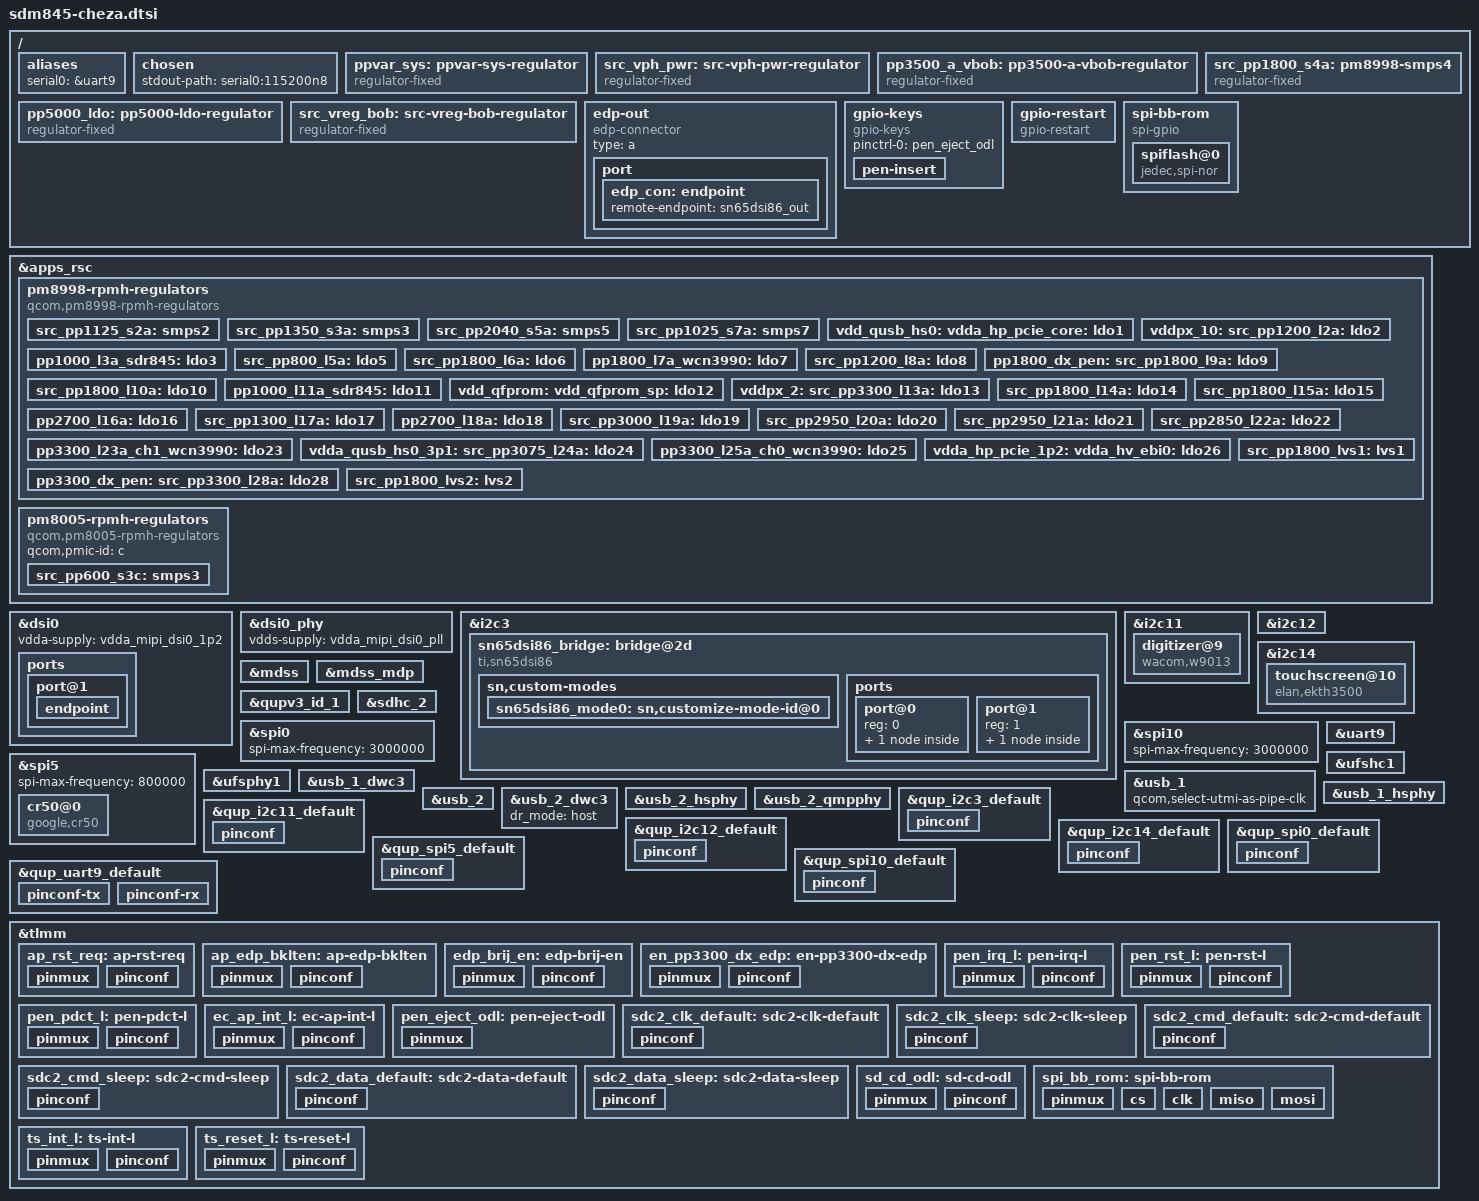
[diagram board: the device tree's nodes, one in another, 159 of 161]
// SPDX-License-Identifier: (GPL-2.0+ OR MIT)
/*
 * Google Cheza device tree source (common between revisions)
 *
 * Copyright 2018 Google LLC.
 */

#include <dt-bindings/gpio/gpio.h>
#include <dt-bindings/input/input.h>
#include <dt-bindings/regulator/qcom,rpmh-regulator.h>
#include "sdm845.dtsi"

/* PMICs depend on spmi_bus label and so must come after SoC */
#include "pm8005.dtsi"
#include "pm8998.dtsi"

/ {
	aliases {
		serial0 = &uart9;
	};

	chosen {
		stdout-path = "serial0:115200n8";
	};

	/* FIXED REGULATORS - parents above childeren */

	ppvar_sys: ppvar-sys-regulator {
		compatible = "regulator-fixed";
		regulator-name = "ppvar_sys";
		regulator-always-on;
		regulator-boot-on;
	};

	src_vph_pwr: src-vph-pwr-regulator {
		compatible = "regulator-fixed";
		regulator-name = "src_vph_pwr";

		/* EC turns on with switchcap_on_l; always on for AP */
		regulator-always-on;
		regulator-boot-on;

		/* TODO: What voltage? */

		vin-supply = <&ppvar_sys>;
	};

	pp3500_a_vbob: pp3500-a-vbob-regulator {
		compatible = "regulator-fixed";
		regulator-name = "vreg_bob";

		/* Comes on automatically when pp5000_ldo comes on */
		regulator-always-on;
		regulator-boot-on;
		regulator-min-microvolt = <3500000>;
		regulator-max-microvolt = <3500000>;

		vin-supply = <&ppvar_sys>;
	};

	pp5000_ldo: pp5000-ldo-regulator {
		compatible = "regulator-fixed";
		regulator-name = "pp5000_ldo";

		/* EC turns on with en_pp5000_a; always on for AP */
		regulator-always-on;
		regulator-boot-on;
		regulator-min-microvolt = <5000000>;
		regulator-max-microvolt = <5000000>;

		vin-supply = <&ppvar_sys>;
	};

	src_vreg_bob: src-vreg-bob-regulator {
		compatible = "regulator-fixed";
		regulator-name = "src_vreg_bob";

		/* EC turns on with vbob_en; always on for AP */
		regulator-always-on;
		regulator-boot-on;
		regulator-min-microvolt = <3500000>;
		regulator-max-microvolt = <3500000>;

		vin-supply = <&pp3500_a_vbob>;
	};

	/*
	 * Apparently RPMh does not provide support for PM8998 S4 because it
	 * is always-on; model it as a fixed regulator.
	 */
	src_pp1800_s4a: pm8998-smps4 {
		compatible = "regulator-fixed";
		regulator-name = "src_pp1800_s4a";

		regulator-min-microvolt = <1800000>;
		regulator-max-microvolt = <1800000>;

		regulator-always-on;
		regulator-boot-on;
	};

	/* BOARD-SPECIFIC TOP LEVEL NODES */

	/* TODO: what is this? */
	edp-out {
		compatible = "edp-connector";
		type = "a";

		port {
			edp_con: endpoint {
				remote-endpoint = <&sn65dsi86_out>;
			};
		};
	};

	gpio-keys {
		compatible = "gpio-keys";
		pinctrl-names = "default";
		pinctrl-0 = <&pen_eject_odl>;

		pen-insert {
			label = "Pen Insert";
			/* Insert = low, eject = high */
			gpios = <&tlmm 119 GPIO_ACTIVE_LOW>;
			linux,code = <SW_PEN_INSERTED>;
			linux,input-type = <EV_SW>;
			wakeup-source;
		};
	};

	gpio-restart {
		compatible = "gpio-restart";
		gpios = <&tlmm 116 GPIO_ACTIVE_HIGH>;
		pinctrl-names = "default";
		pinctrl-0 = <&ap_rst_req>;
		priority = <200>;
	};

	spi-bb-rom {
		compatible = "spi-gpio";
		#address-cells = <0x1>;
		#size-cells = <0x0>;

		gpio-sck = <&tlmm 95 0>;
		gpio-miso = <&tlmm 92 0>;
		gpio-mosi = <&tlmm 91 0>;
		cs-gpios = <&tlmm 90 0>;
		num-chipselects = <1>;
		pinctrl-names = "default";
		pinctrl-0 = <&spi_bb_rom>;

		spiflash@0 {
			compatible = "jedec,spi-nor";
			reg = <0>;
			spi-max-frequency = <38000000>;
		};
	};
};

&apps_rsc {
	pm8998-rpmh-regulators {
		compatible = "qcom,pm8998-rpmh-regulators";
		qcom,pmic-id = "a";

		vdd-s1-supply = <&src_vph_pwr>;
		vdd-s2-supply = <&src_vph_pwr>;
		vdd-s3-supply = <&src_vph_pwr>;
		vdd-s4-supply = <&src_vph_pwr>;
		vdd-s5-supply = <&src_vph_pwr>;
		vdd-s6-supply = <&src_vph_pwr>;
		vdd-s7-supply = <&src_vph_pwr>;
		vdd-s8-supply = <&src_vph_pwr>;
		vdd-s9-supply = <&src_vph_pwr>;
		vdd-s10-supply = <&src_vph_pwr>;
		vdd-s11-supply = <&src_vph_pwr>;
		vdd-s12-supply = <&src_vph_pwr>;
		vdd-s13-supply = <&src_vph_pwr>;
		vdd-l1-l27-supply = <&src_pp1025_s7a>;
		vdd-l2-l8-l17-supply = <&src_pp1350_s3a>;
		vdd-l3-l11-supply = <&src_pp1025_s7a>;
		vdd-l4-l5-supply = <&src_pp1025_s7a>;
		vdd-l6-supply = <&src_vph_pwr>;
		vdd-l7-l12-l14-l15-supply = <&src_pp2040_s5a>;
		vdd-l9-supply = <&src_pp2040_s5a>;
		vdd-l10-l23-l25-supply = <&src_vreg_bob>;
		vdd-l13-l19-l21-supply = <&src_vreg_bob>;
		vdd-l16-l28-supply = <&src_vreg_bob>;
		vdd-l18-l22-supply = <&src_vreg_bob>;
		vdd-l20-l24-supply = <&src_vreg_bob>;
		vdd-l26-supply = <&src_pp1350_s3a>;
		vin-lvs-1-2-supply = <&src_pp1800_s4a>;

		src_pp1125_s2a: smps2 {
			regulator-min-microvolt = <1100000>;
			regulator-max-microvolt = <1100000>;
		};

		src_pp1350_s3a: smps3 {
			regulator-min-microvolt = <1352000>;
			regulator-max-microvolt = <1352000>;
		};

		src_pp2040_s5a: smps5 {
			regulator-min-microvolt = <1904000>;
			regulator-max-microvolt = <2040000>;
		};

		src_pp1025_s7a: smps7 {
			regulator-min-microvolt = <900000>;
			regulator-max-microvolt = <1028000>;
		};

		/* TODO: src_pp750_s10_11_12a_a: smps10 */
		/* TODO: src_pp750_s10_11_12a_b: smps11 */
		/* TODO: src_pp750_s10_11_12a_c: smps12 */
		/* TODO: src_pp750_s13a: smps13 */

		vdd_qusb_hs0:
		vdda_hp_pcie_core:
		vdda_mipi_csi0_0p9:
		vdda_mipi_csi1_0p9:
		vdda_mipi_csi2_0p9:
		vdda_mipi_dsi0_pll:
		vdda_mipi_dsi1_pll:
		vdda_qlink_lv:
		vdda_qlink_lv_ck:
		vdda_qrefs_0p875:
		vdda_pcie_core:
		vdda_pll_cc_ebi01:
		vdda_pll_cc_ebi23:
		vdda_sp_sensor:
		vdda_ufs1_core:
		vdda_ufs2_core:
		vdda_usb1_ss_core:
		vdda_usb2_ss_core:
		src_pp875_l1a: ldo1 {
			regulator-min-microvolt = <880000>;
			regulator-max-microvolt = <880000>;
			regulator-initial-mode =
				<RPMH_REGULATOR_MODE_LPM>;
			regulator-allow-set-load;
			regulator-allowed-modes =
				<RPMH_REGULATOR_MODE_LPM
				 RPMH_REGULATOR_MODE_HPM>;
		};

		vddpx_10:
		src_pp1200_l2a: ldo2 {
			regulator-min-microvolt = <1200000>;
			regulator-max-microvolt = <1200000>;
			regulator-initial-mode =
				<RPMH_REGULATOR_MODE_LPM>;
			regulator-allow-set-load;
			regulator-allowed-modes =
				<RPMH_REGULATOR_MODE_LPM
				 RPMH_REGULATOR_MODE_HPM>;
			regulator-always-on;
		};

		pp1000_l3a_sdr845: ldo3 {
			regulator-min-microvolt = <1000000>;
			regulator-max-microvolt = <1000000>;
			regulator-initial-mode =
				<RPMH_REGULATOR_MODE_LPM>;
			regulator-allow-set-load;
			regulator-allowed-modes =
				<RPMH_REGULATOR_MODE_LPM
				 RPMH_REGULATOR_MODE_HPM>;
		};

		src_pp800_l5a: ldo5 {
			regulator-min-microvolt = <800000>;
			regulator-max-microvolt = <800000>;
			regulator-initial-mode =
				<RPMH_REGULATOR_MODE_LPM>;
			regulator-allow-set-load;
			regulator-allowed-modes =
				<RPMH_REGULATOR_MODE_LPM
				 RPMH_REGULATOR_MODE_HPM>;
		};

		src_pp1800_l6a: ldo6 {
			regulator-min-microvolt = <1856000>;
			regulator-max-microvolt = <1856000>;
			regulator-initial-mode =
				<RPMH_REGULATOR_MODE_LPM>;
			regulator-allow-set-load;
			regulator-allowed-modes =
				<RPMH_REGULATOR_MODE_LPM
				 RPMH_REGULATOR_MODE_HPM>;
		};

		pp1800_l7a_wcn3990: ldo7 {
			regulator-min-microvolt = <1800000>;
			regulator-max-microvolt = <1800000>;
			regulator-initial-mode =
				<RPMH_REGULATOR_MODE_LPM>;
			regulator-allow-set-load;
			regulator-allowed-modes =
				<RPMH_REGULATOR_MODE_LPM
				 RPMH_REGULATOR_MODE_HPM>;
		};

		src_pp1200_l8a: ldo8 {
			regulator-min-microvolt = <1200000>;
			regulator-max-microvolt = <1248000>;
			regulator-initial-mode =
				<RPMH_REGULATOR_MODE_LPM>;
			regulator-allow-set-load;
			regulator-allowed-modes =
				<RPMH_REGULATOR_MODE_LPM
				 RPMH_REGULATOR_MODE_HPM>;
		};

		pp1800_dx_pen:
		src_pp1800_l9a: ldo9 {
			regulator-min-microvolt = <1704000>;
			regulator-max-microvolt = <2928000>;
			regulator-initial-mode =
				<RPMH_REGULATOR_MODE_LPM>;
			regulator-allow-set-load;
			regulator-allowed-modes =
				<RPMH_REGULATOR_MODE_LPM
				 RPMH_REGULATOR_MODE_HPM>;
		};

		src_pp1800_l10a: ldo10 {
			regulator-min-microvolt = <1704000>;
			regulator-max-microvolt = <2928000>;
			regulator-initial-mode =
				<RPMH_REGULATOR_MODE_LPM>;
			regulator-allow-set-load;
			regulator-allowed-modes =
				<RPMH_REGULATOR_MODE_LPM
				 RPMH_REGULATOR_MODE_HPM>;
		};

		pp1000_l11a_sdr845: ldo11 {
			regulator-min-microvolt = <1000000>;
			regulator-max-microvolt = <1048000>;
			regulator-initial-mode =
				<RPMH_REGULATOR_MODE_LPM>;
			regulator-allow-set-load;
			regulator-allowed-modes =
				<RPMH_REGULATOR_MODE_LPM
				 RPMH_REGULATOR_MODE_HPM>;
		};

		vdd_qfprom:
		vdd_qfprom_sp:
		vdda_apc1_cs_1p8:
		vdda_gfx_cs_1p8:
		vdda_qrefs_1p8:
		vdda_qusb_hs0_1p8:
		vddpx_11:
		src_pp1800_l12a: ldo12 {
			regulator-min-microvolt = <1800000>;
			regulator-max-microvolt = <1800000>;
			regulator-initial-mode =
				<RPMH_REGULATOR_MODE_LPM>;
			regulator-allow-set-load;
			regulator-allowed-modes =
				<RPMH_REGULATOR_MODE_LPM
				 RPMH_REGULATOR_MODE_HPM>;
		};

		/*
		 * NOTE: this rail should have been called
		 * src_pp2950_l13a in the schematic
		 */
		vddpx_2:
		src_pp3300_l13a: ldo13 {
			regulator-min-microvolt = <1800000>;
			regulator-max-microvolt = <2960000>;
			regulator-initial-mode =
				<RPMH_REGULATOR_MODE_LPM>;
			regulator-allow-set-load;
			regulator-allowed-modes =
				<RPMH_REGULATOR_MODE_LPM
				 RPMH_REGULATOR_MODE_HPM>;
		};

		src_pp1800_l14a: ldo14 {
			regulator-min-microvolt = <1800000>;
			regulator-max-microvolt = <1880000>;
			regulator-initial-mode =
				<RPMH_REGULATOR_MODE_LPM>;
			regulator-allow-set-load;
			regulator-allowed-modes =
				<RPMH_REGULATOR_MODE_LPM
				 RPMH_REGULATOR_MODE_HPM>;
		};

		src_pp1800_l15a: ldo15 {
			regulator-min-microvolt = <1800000>;
			regulator-max-microvolt = <1800000>;
			regulator-initial-mode =
				<RPMH_REGULATOR_MODE_LPM>;
			regulator-allow-set-load;
			regulator-allowed-modes =
				<RPMH_REGULATOR_MODE_LPM
				 RPMH_REGULATOR_MODE_HPM>;
		};

		pp2700_l16a: ldo16 {
			regulator-min-microvolt = <2704000>;
			regulator-max-microvolt = <2704000>;
			regulator-initial-mode =
				<RPMH_REGULATOR_MODE_LPM>;
			regulator-allow-set-load;
			regulator-allowed-modes =
				<RPMH_REGULATOR_MODE_LPM
				 RPMH_REGULATOR_MODE_HPM>;
		};

		src_pp1300_l17a: ldo17 {
			regulator-min-microvolt = <1304000>;
			regulator-max-microvolt = <1304000>;
			regulator-initial-mode =
				<RPMH_REGULATOR_MODE_LPM>;
			regulator-allow-set-load;
			regulator-allowed-modes =
				<RPMH_REGULATOR_MODE_LPM
				 RPMH_REGULATOR_MODE_HPM>;
		};

		pp2700_l18a: ldo18 {
			regulator-min-microvolt = <2704000>;
			regulator-max-microvolt = <2960000>;
			regulator-initial-mode =
				<RPMH_REGULATOR_MODE_LPM>;
			regulator-allow-set-load;
			regulator-allowed-modes =
				<RPMH_REGULATOR_MODE_LPM
				 RPMH_REGULATOR_MODE_HPM>;
		};

		src_pp3000_l19a: ldo19 {
			regulator-min-microvolt = <2856000>;
			regulator-max-microvolt = <3104000>;
			regulator-initial-mode =
				<RPMH_REGULATOR_MODE_LPM>;
			regulator-allow-set-load;
			regulator-allowed-modes =
				<RPMH_REGULATOR_MODE_LPM
				 RPMH_REGULATOR_MODE_HPM>;
		};

		src_pp2950_l20a: ldo20 {
			regulator-min-microvolt = <2704000>;
			regulator-max-microvolt = <2960000>;
			regulator-initial-mode =
				<RPMH_REGULATOR_MODE_LPM>;
			regulator-allow-set-load;
			regulator-allowed-modes =
				<RPMH_REGULATOR_MODE_LPM
				 RPMH_REGULATOR_MODE_HPM>;
		};

		src_pp2950_l21a: ldo21 {
			regulator-min-microvolt = <2704000>;
			regulator-max-microvolt = <2960000>;
			regulator-initial-mode =
				<RPMH_REGULATOR_MODE_LPM>;
			regulator-allow-set-load;
			regulator-allowed-modes =
				<RPMH_REGULATOR_MODE_LPM
				 RPMH_REGULATOR_MODE_HPM>;
		};

		src_pp2850_l22a: ldo22 {
			regulator-min-microvolt = <2864000>;
			regulator-max-microvolt = <3312000>;
			regulator-initial-mode =
				<RPMH_REGULATOR_MODE_LPM>;
			regulator-allow-set-load;
			regulator-allowed-modes =
				<RPMH_REGULATOR_MODE_LPM
				 RPMH_REGULATOR_MODE_HPM>;
		};

		pp3300_l23a_ch1_wcn3990: ldo23 {
			regulator-min-microvolt = <3000000>;
			regulator-max-microvolt = <3312000>;
			regulator-initial-mode =
				<RPMH_REGULATOR_MODE_LPM>;
			regulator-allow-set-load;
			regulator-allowed-modes =
				<RPMH_REGULATOR_MODE_LPM
				 RPMH_REGULATOR_MODE_HPM>;
		};

		vdda_qusb_hs0_3p1:
		src_pp3075_l24a: ldo24 {
			regulator-min-microvolt = <3088000>;
			regulator-max-microvolt = <3088000>;
			regulator-initial-mode =
				<RPMH_REGULATOR_MODE_LPM>;
			regulator-allow-set-load;
			regulator-allowed-modes =
				<RPMH_REGULATOR_MODE_LPM
				 RPMH_REGULATOR_MODE_HPM>;
		};

		pp3300_l25a_ch0_wcn3990: ldo25 {
			regulator-min-microvolt = <3000000>;
			regulator-max-microvolt = <3312000>;
			regulator-initial-mode =
				<RPMH_REGULATOR_MODE_LPM>;
			regulator-allow-set-load;
			regulator-allowed-modes =
				<RPMH_REGULATOR_MODE_LPM
				 RPMH_REGULATOR_MODE_HPM>;
		};

		vdda_hp_pcie_1p2:
		vdda_hv_ebi0:
		vdda_hv_ebi1:
		vdda_hv_ebi2:
		vdda_hv_ebi3:
		vdda_mipi_csi_1p25:
		vdda_mipi_dsi0_1p2:
		vdda_mipi_dsi1_1p2:
		vdda_pcie_1p2:
		vdda_ufs1_1p2:
		vdda_ufs2_1p2:
		vdda_usb1_ss_1p2:
		vdda_usb2_ss_1p2:
		src_pp1200_l26a: ldo26 {
			regulator-min-microvolt = <1200000>;
			regulator-max-microvolt = <1200000>;
			regulator-initial-mode =
				<RPMH_REGULATOR_MODE_LPM>;
			regulator-allow-set-load;
			regulator-allowed-modes =
				<RPMH_REGULATOR_MODE_LPM
				 RPMH_REGULATOR_MODE_HPM>;
		};

		pp3300_dx_pen:
		src_pp3300_l28a: ldo28 {
			regulator-min-microvolt = <2856000>;
			regulator-max-microvolt = <3008000>;
			regulator-initial-mode =
				<RPMH_REGULATOR_MODE_LPM>;
			regulator-allow-set-load;
			regulator-allowed-modes =
				<RPMH_REGULATOR_MODE_LPM
				 RPMH_REGULATOR_MODE_HPM>;
		};

		src_pp1800_lvs1: lvs1 {
			regulator-min-microvolt = <1800000>;
			regulator-max-microvolt = <1800000>;
		};

		src_pp1800_lvs2: lvs2 {
			regulator-min-microvolt = <1800000>;
			regulator-max-microvolt = <1800000>;
		};
	};

	pm8005-rpmh-regulators {
		compatible = "qcom,pm8005-rpmh-regulators";
		qcom,pmic-id = "c";

		src_pp600_s3c: smps3 {
			regulator-min-microvolt = <600000>;
			regulator-max-microvolt = <600000>;
		};
	};
};

&dsi0 {
	status = "okay";
	vdda-supply = <&vdda_mipi_dsi0_1p2>;

	ports {
		port@1 {
			endpoint {
				remote-endpoint = <&sn65dsi86_in>;
				data-lanes = <0 1 2 3>;
			};
		};
	};
};

&dsi0_phy {
	status = "okay";
	vdds-supply = <&vdda_mipi_dsi0_pll>;
};

edp_brij_i2c: &i2c3 {
	status = "okay";

	/* TODO: clock-frequency? */

	sn65dsi86_bridge: bridge@2d {
		#address-cells = <2>;
		#size-cells = <1>;

		status = "okay";

		compatible = "ti,sn65dsi86";
		reg = <0x2d>;

		interrupt-parent = <&tlmm>;
		interrupts = <31 2>;

		sn,irq-gpio = <&tlmm 32 0>;
		sn,panel-bklt-en = <&tlmm 37 0>;
		sn,panel-bias-en = <&tlmm 102 0>;

		vpll-supply = <&src_pp1800_s4a>;
		vcca-supply = <&src_pp1200_l2a>;

		clocks = <&rpmhcc RPMH_LN_BB_CLK2>;
		clock-names = "refclk";

		/* TODO: need a sleep config? */
		pinctrl-names = "default";
		pinctrl-0 = <&ap_edp_bklten &edp_brij_en &en_pp3300_dx_edp>;
		#sound-dai-cells = <1>;

		sn,custom-modes {
			sn65dsi86_mode0: sn,customize-mode-id@0 {
				sn,mode-h-active = <2160>;
				sn,mode-h-front-porch = <48>;
				sn,mode-h-pulse-width = <32>;
				sn,mode-h-back-porch = <80>;
				sn,mode-h-active-high;
				sn,mode-v-active = <1440>;
				sn,mode-v-front-porch = <3>;
				sn,mode-v-pulse-width = <10>;
				sn,mode-v-back-porch = <27>;
				sn,mode-v-active-high;
				sn,mode-refresh-rate = <60>;
				sn,mode-clock-in-khz = <205000>;

			};
		};

		ports {
			#address-cells = <1>;
			#size-cells = <0>;

			port@0 {
				reg = <0>;
				sn65dsi86_in: endpoint {
					remote-endpoint = <&dsi0_out>;
				};
			};

			port@1 {
				reg = <1>;
				sn65dsi86_out: endpoint {
				remote-endpoint = <&edp_con>;
				};
			};
		};
	};
};

ap_pen_1v8: &i2c11 {
	status = "okay";

	/* TODO: clock-frequency? */

	digitizer@9 {
		compatible = "wacom,w9013", "hid-over-i2c";
		reg = <0x9>;
		pinctrl-names = "default";
		pinctrl-0 = <&pen_irq_l>, <&pen_pdct_l>, <&pen_rst_l>;

		vdd-supply = <&pp3300_dx_pen>;
		vddl-supply = <&pp1800_dx_pen>;
		post-power-on-delay-ms = <100>;

		interrupt-parent = <&tlmm>;
		interrupts = <24 IRQ_TYPE_LEVEL_LOW>;

		hid-descr-addr = <0x1>;
	};
};

amp_i2c: &i2c12 {
	status = "okay";

	/* TODO: clock-frequency? */
};

ap_ts_i2c: &i2c14 {
	status = "okay";

	/* TODO: clock-frequency? */

	touchscreen@10 {
		compatible = "elan,ekth3500";
		reg = <0x10>;
		pinctrl-names = "default";
		pinctrl-0 = <&ts_int_l &ts_reset_l>;

		interrupt-parent = <&tlmm>;
		interrupts = <125 IRQ_TYPE_LEVEL_LOW>;

		vcc33-supply = <&src_pp3300_l28a>;

		reset-gpios = <&tlmm 118 GPIO_ACTIVE_LOW>;
	};
};

&mdss {
	status = "okay";
};

&mdss_mdp {
	status = "okay";
};

&qupv3_id_1 {
	status = "okay";
};

&sdhc_2 {
	status = "okay";

	pinctrl-names = "default", "sleep";
	pinctrl-0 = <&sdc2_clk_default  &sdc2_cmd_default &sdc2_data_default
		     &sd_cd_odl>;
	pinctrl-1 = <&sdc2_clk_sleep &sdc2_cmd_sleep &sdc2_data_sleep
		     &sd_cd_odl>;

	vdd-supply = <&src_pp2950_l21a>;
	qcom,vdd-voltage-level = <2950000 2960000>;
	qcom,vdd-current-level = <200 800000>;

	vdd-io-supply = <&vddpx_2>;
	qcom,vdd-io-voltage-level = <1808000 2960000>;
	qcom,vdd-io-current-level = <200 22000>;

	cd-gpios = <&tlmm 44 GPIO_ACTIVE_LOW>;
};

&spi0 {
	status = "okay";
	spi-max-frequency = <3000000>;  /* TODO: Drop this? */
};

&spi10 {
	status = "okay";
	spi-max-frequency = <3000000>;  /* TODO: Drop this? */
};

&spi5 {
	status = "okay";
	spi-max-frequency = <800000>; /* TODO: Drop this */
	cr50@0 {
		compatible = "google,cr50";
		reg = <0>;
		spi-max-frequency = <800000>;
		interrupt-parent = <&tlmm>;
		interrupts = <129 IRQ_TYPE_EDGE_RISING>;
	};
};

&uart9 {
	status = "okay";
};

&ufshc1 {
	status = "okay";

	vcc-supply = <&src_pp2950_l20a>;
	vcc-voltage-level = <2950000 2960000>;
	vcc-max-microamp = <600000>;
	vccq2-max-microamp = <600000>;

	qcom,vddp-ref-clk-supply = <&vddpx_10>;
	qcom,vddp-ref-clk-max-microamp = <100>;
};

&ufsphy1 {
	status = "okay";

	vdda-phy-supply = <&vdda_ufs1_core>;
	vdda-pll-supply = <&vdda_ufs1_1p2>;
	vdda-phy-max-microamp = <62900>;
	vdda-pll-max-microamp = <18300>;
};

&usb_1 {
	status = "okay";

	/* We'll use this as USB 2.0 only */
	qcom,select-utmi-as-pipe-clk;
};

&usb_1_dwc3 {
	/*
	 * The hardware design intends this port to be hooked up in peripheral
	 * mode, so we'll hardcode it here.  Some details:
	 * - SDM845 expects only a single Type C connector so it has only one
	 *   native Type C port but cheza has two Type C connectors.
	 * - The only source of DP is the single native Type C port.
	 * - On cheza we want to be able to hook DP up to _either_ of the
	 *   two Type C connectors and want to be able to achieve 4 lanes of DP.
	 * - When you configure a Type C port for 4 lanes of DP you lose USB3.
	 * - In order to make everything work, the native Type C port is always
	 *   configured as 4-lanes DP so it's always available.
	 * - The extra USB3 port on SDM845 goes to a USB 3 hub which is then
	 *   sent to the two Type C connectors.
	 * - The extra USB2 lines from the native Type C port are always
	 *   setup as "peripheral" so that we can mux them over to one connector
	 *   or the other if someone needs the connector configured as a gadget
	 *   (but they only get USB2 speeds).
	 *
	 * All the hardware muxes would allow us to hook things up in different
	 * ways to some potential benefit for static configurations (you could
	 * achieve extra USB2 bandwidth by using two different ports for the
	 * two conenctors or possibly even get USB3 peripheral mode), but in
	 * each case you end up forcing to disconnect/reconnect an in-use
	 * USB session in some cases depending on what you hotplug into the
	 * other connector.  Thus hardcoding this as peripheral makes sense.
	 */
	dr_mode = "peripheral";

	/*
	 * We always need the high speed pins as 4-lanes DP in case someone
	 * hotplugs a DP peripheral.  Thus limit this port to a max of high
	 * speed.
	 */
	maximum-speed = "high-speed";

	/*
	 * We don't need the usb3-phy since we run in highspeed mode always, so
	 * re-define these properties removing the superspeed USB PHY reference.
	 */
	phys = <&usb_1_hsphy>;
	phy-names = "usb2-phy";
};

&usb_1_hsphy {
	status = "okay";

	vdd-supply = <&vdda_usb1_ss_core>;
	vdda-pll-supply = <&vdda_qusb_hs0_1p8>;
	vdda-phy-dpdm-supply = <&vdda_qusb_hs0_3p1>;
};

&usb_2 {
	status = "okay";
};

&usb_2_dwc3 {
	/* We have this hooked up to a hub and we always use in host mode */
	dr_mode = "host";
};

&usb_2_hsphy {
	status = "okay";

	vdd-supply = <&vdda_usb2_ss_core>;
	vdda-pll-supply = <&vdda_qusb_hs0_1p8>;
	vdda-phy-dpdm-supply = <&vdda_qusb_hs0_3p1>;
};

&usb_2_qmpphy {
	status = "okay";

	vdda-phy-supply = <&vdda_usb2_ss_1p2>;
	vdda-pll-supply = <&vdda_usb2_ss_core>;
};

/* PINCTRL - additions to nodes defined in sdm845.dtsi */

&qup_i2c3_default {
	pinconf {
		pins = "gpio41", "gpio42";
		drive-strength = <2>;

		/* Has external pullup */
		bias-disable;
	};
};

&qup_i2c11_default {
	pinconf {
		pins = "gpio31", "gpio32";
		drive-strength = <2>;

		/* Has external pullup */
		bias-disable;
	};
};

&qup_i2c12_default {
	pinconf {
		pins = "gpio49", "gpio50";
		drive-strength = <2>;

		/* Has external pullup */
		bias-disable;
	};
};

&qup_i2c14_default {
	pinconf {
		pins = "gpio33", "gpio34";
		drive-strength = <2>;

		/* Has external pullup */
		bias-disable;
	};
};

&qup_spi0_default {
	pinconf {
		pins = "gpio0", "gpio1", "gpio2", "gpio3";
		drive-strength = <2>;
		bias-disable;
	};
};

&qup_spi5_default {
	pinconf {
		pins = "gpio85", "gpio86", "gpio87", "gpio88";
		/* TODO: drive strength 6 mA is right? */
		drive-strength = <6>;
		bias-disable;
	};
};

&qup_spi10_default {
	pinconf {
		pins = "gpio53", "gpio54", "gpio55", "gpio56";
		drive-strength = <2>;
		bias-disable;
	};
};

&qup_uart9_default {
	pinconf-tx {
		pins = "gpio4";
		drive-strength = <2>;
		bias-disable;
	};

	pinconf-rx {
		pins = "gpio5";
		drive-strength = <2>;
		bias-pull-up;
	};
};

/* PINCTRL - board-specific pinctrl */

&tlmm {
	ap_rst_req: ap-rst-req {
		pinmux {
			pins = "gpio116";
			function = "gpio";
		};

		pinconf {
			pins = "gpio116";
			bias-disable;
		};
	};

	ap_edp_bklten: ap-edp-bklten {
		pinmux {
			pins = "gpio37";
			function = "gpio";
		};

		pinconf {
			pins = "gpio37";
			drive-strength = <8>; /* TODO: why? */
			bias-disable;
		};
	};

	edp_brij_en: edp-brij-en {
		pinmux {
			pins = "gpio102";
			function = "gpio";
		};

		pinconf {
			pins = "gpio102";
			drive-strength = <8>; /* TODO: why? */
			bias-disable;
		};
	};

	en_pp3300_dx_edp: en-pp3300-dx-edp {
		pinmux {
			pins = "gpio43";
			function = "gpio";
		};

		pinconf {
			pins = "gpio43";
			drive-strength = <8>; /* TODO: why? */
			bias-disable;
		};
	};

	pen_irq_l: pen-irq-l {
		pinmux {
			pins = "gpio24";
			function = "gpio";
		};

		pinconf {
			pins = "gpio24";

			/* Has external pullup */
			bias-disable;
		};
	};

	pen_rst_l: pen-rst-l {
		pinmux  {
			pins = "gpio23";
			function = "gpio";
		};

		pinconf {
			pins = "gpio23";

			/* TODO: shouldn't specify high here? */
			output-high;
		};
	};

	pen_pdct_l: pen-pdct-l {
		pinmux {
			pins = "gpio63";
			function = "gpio";
		};

		pinconf {
			pins = "gpio63";

			/* Has external pullup */
			bias-disable;
		};
	};

	ec_ap_int_l: ec-ap-int-l {
		pinmux {
		       pins = "gpio122";
		       function = "gpio";
		       input-enable; /* ? */
		};

		pinconf {
		       pins = "gpio122";
		       bias-pull-up;
		};
	};

	pen_eject_odl: pen-eject-odl {
		pinmux {
			pins = "gpio119";
			function = "gpio";
			bias-pull-up;
		};
	};

	sdc2_clk_default: sdc2-clk-default {
		pinconf {
			pins = "sdc2_clk";
			bias-disable;
			drive-strength = <16>;
		};
	};

	sdc2_clk_sleep: sdc2-clk-sleep {
		pinconf {
			pins = "sdc2_clk";
			bias-disable;
			drive-strength = <2>;
		};
	};

	sdc2_cmd_default: sdc2-cmd-default {
		pinconf {
			pins = "sdc2_cmd";
			bias-pull-up;
			drive-strength = <10>;
		};
	};

	sdc2_cmd_sleep: sdc2-cmd-sleep {
		pinconf {
			pins = "sdc2_cmd";
			bias-pull-up;
			drive-strength = <2>;
		};
	};

	sdc2_data_default: sdc2-data-default {
		pinconf {
			pins = "sdc2_data";
			bias-pull-up;
			drive-strength = <10>;
		};
	};

	sdc2_data_sleep: sdc2-data-sleep {
		pinconf {
			pins = "sdc2_data";
			bias-pull-up;
			drive-strength = <2>;
		};
	};

	sd_cd_odl: sd-cd-odl {
		pinmux {
			pins = "gpio44";
			function = "gpio";
		};

		pinconf {
			pins = "gpio44";
			bias-pull-up;
			drive-strength = <2>;
		};
	};

	spi_bb_rom: spi-bb-rom {
		pinmux {
			function = "gpio";
			pins = "gpio90", "gpio91", "gpio92", "gpio95";
		};
		cs {
			pins = "gpio90";
			bias-disable;
			output-high;
		};
		clk {
			pins = "gpio95";
			bias-pull-down;
			output-low;
		};
		miso {
			pins = "gpio92";
			bias-pull-down;
			input-enable;
		};
		mosi {
			pins = "gpio91";
			bias-pull-down;
			output-low;
		};
	};

	ts_int_l: ts-int-l {
		pinmux  {
			pins = "gpio125";
			function = "gpio";
		};

		pinconf {
			pins = "gpio125";
			bias-pull-up;
		};
	};

	ts_reset_l: ts-reset-l {
		pinmux  {
			pins = "gpio118";
			function = "gpio";
		};

		pinconf {
			pins = "gpio118";

			/* TODO: shouldn't specify high here? */
			output-high;
		};
	};
};
